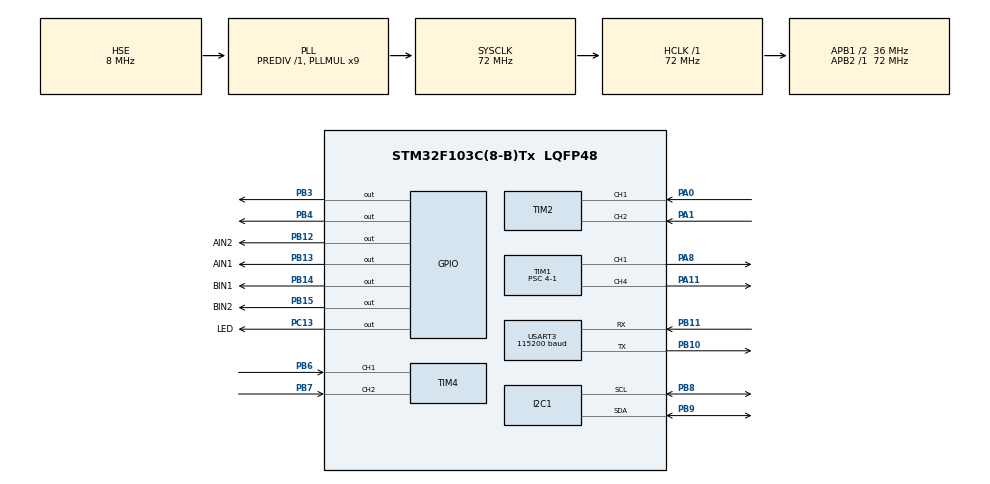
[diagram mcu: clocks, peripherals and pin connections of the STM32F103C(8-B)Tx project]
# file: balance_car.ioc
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Dma.Request0=USART3_RX
Dma.USART3_RX.0.Direction=DMA_PERIPH_TO_MEMORY
Dma.USART3_RX.0.Instance=DMA1_Channel3
Dma.USART3_RX.0.MemDataAlignment=DMA_MDATAALIGN_BYTE
Dma.USART3_RX.0.MemInc=DMA_MINC_ENABLE
Dma.USART3_RX.0.Mode=DMA_NORMAL
Dma.USART3_RX.0.PeriphDataAlignment=DMA_PDATAALIGN_BYTE
Dma.USART3_RX.0.PeriphInc=DMA_PINC_DISABLE
Dma.USART3_RX.0.Priority=DMA_PRIORITY_LOW
FREERTOS.Tasks01=defaultTask,-3,128,StartDefaultTask,Default,NULL,Dynamic,NULL,NULL;sensor,2,128,sensor_task,As external,NULL,Dynamic,NULL,NULL;motor,0,128,motor_task,As external,NULL,Dynamic,NULL,NULL;Bluetooth,0,128,Bluetooth_task,As external,NULL,Dynamic,NULL,NULL
Mcu.Family=STM32F1
Mcu.Name=STM32F103C(8-B)Tx
Mcu.Package=LQFP48
NVIC.DMA1_Channel3_IRQn=true\:5\:0\:false\:false\:true\:true\:false\:true\:true
NVIC.PriorityGroup=NVIC_PRIORITYGROUP_4
NVIC.TIM3_IRQn=true\:15\:0\:false\:false\:true\:false\:false\:true\:true
NVIC.TimeBase=TIM3_IRQn
NVIC.TimeBaseIP=TIM3
NVIC.USART3_IRQn=true\:5\:0\:false\:false\:true\:true\:true\:true\:true
PA0-WKUP.Signal=S_TIM2_CH1_ETR
PA1.Signal=S_TIM2_CH2
PA11.Signal=S_TIM1_CH4
PA13.Mode=Serial_Wire
PA13.Signal=SYS_JTMS-SWDIO
PA14.Mode=Serial_Wire
PA14.Signal=SYS_JTCK-SWCLK
PA8.Signal=S_TIM1_CH1
PB10.Mode=Asynchronous
PB10.Signal=USART3_TX
PB11.Mode=Asynchronous
PB11.Signal=USART3_RX
PB12.GPIO_Label=AIN2
PB12.GPIO_PuPd=GPIO_PULLDOWN
PB12.Signal=GPIO_Output
PB13.GPIO_Label=AIN1
PB13.GPIO_PuPd=GPIO_PULLDOWN
PB13.Signal=GPIO_Output
PB14.GPIO_Label=BIN1
PB14.GPIO_PuPd=GPIO_PULLDOWN
PB14.Signal=GPIO_Output
PB15.GPIO_Label=BIN2
PB15.GPIO_PuPd=GPIO_PULLDOWN
PB15.Signal=GPIO_Output
PB3.GPIO_ModeDefaultOutputPP=GPIO_MODE_OUTPUT_OD
PB3.GPIO_PuPd=GPIO_NOPULL
PB3.GPIO_Speed=GPIO_SPEED_FREQ_HIGH
PB3.PinState=GPIO_PIN_SET
PB3.Signal=GPIO_Output
PB4.GPIO_ModeDefaultOutputPP=GPIO_MODE_OUTPUT_OD
PB4.GPIO_PuPd=GPIO_NOPULL
PB4.GPIO_Speed=GPIO_SPEED_FREQ_HIGH
PB4.PinState=GPIO_PIN_SET
PB4.Signal=GPIO_Output
PB6.Signal=S_TIM4_CH1
PB7.Signal=S_TIM4_CH2
PB8.Mode=I2C
PB8.Signal=I2C1_SCL
PB9.Mode=I2C
PB9.Signal=I2C1_SDA
PC13-TAMPER-RTC.GPIO_Label=LED
PC13-TAMPER-RTC.PinState=GPIO_PIN_SET
PC13-TAMPER-RTC.Signal=GPIO_Output
PD0-OSC_IN.Mode=HSE-External-Oscillator
PD0-OSC_IN.Signal=RCC_OSC_IN
PD1-OSC_OUT.Mode=HSE-External-Oscillator
PD1-OSC_OUT.Signal=RCC_OSC_OUT
ProjectManager.HeapSize=0x200
ProjectManager.StackSize=0x400
ProjectManager.TargetToolchain=MDK-ARM V5
RCC.AHBFreq_Value=72000000
RCC.APB1CLKDivider=RCC_HCLK_DIV2
RCC.APB1Freq_Value=36000000
RCC.APB1TimFreq_Value=72000000
RCC.APB2Freq_Value=72000000
RCC.APB2TimFreq_Value=72000000
RCC.HCLKFreq_Value=72000000
RCC.PLLMUL=RCC_PLL_MUL9
RCC.PLLSourceVirtual=RCC_PLLSOURCE_HSE
RCC.SYSCLKFreq_VALUE=72000000
RCC.SYSCLKSource=RCC_SYSCLKSOURCE_PLLCLK
RCC.USBFreq_Value=72000000
SH.S_TIM1_CH1.0=TIM1_CH1,PWM Generation1 CH1
SH.S_TIM1_CH4.0=TIM1_CH4,PWM Generation4 CH4
SH.S_TIM2_CH1_ETR.0=TIM2_CH1,Encoder_Interface
SH.S_TIM2_CH2.0=TIM2_CH2,Encoder_Interface
SH.S_TIM4_CH1.0=TIM4_CH1,Encoder_Interface
SH.S_TIM4_CH2.0=TIM4_CH2,Encoder_Interface
TIM1.Channel-PWM\ Generation1\ CH1=TIM_CHANNEL_1
TIM1.Channel-PWM\ Generation4\ CH4=TIM_CHANNEL_4
TIM1.Period=900-1
TIM1.Prescaler=4-1
TIM2.EncoderMode=TIM_ENCODERMODE_TI12
TIM2.IC1Filter=8
TIM2.IC2Filter=8
TIM4.EncoderMode=TIM_ENCODERMODE_TI12
TIM4.IC1Filter=8
TIM4.IC2Filter=8
USART3.BaudRate=115200
USART3.VirtualMode=VM_ASYNC
VP_FREERTOS_VS_CMSIS_V1.Mode=CMSIS_V1
VP_SYS_VS_tim3.Mode=TIM3
board=custom

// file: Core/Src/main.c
/* USER CODE BEGIN Header */
/**
  ******************************************************************************
  * @file           : main.c
  * @brief          : Main program body
  ******************************************************************************
  * @attention
  *
  * Copyright (c) 2024 STMicroelectronics.
  * All rights reserved.
  *
  * This software is licensed under terms that can be found in the LICENSE file
  * in the root directory of this software component.
  * If no LICENSE file comes with this software, it is provided AS-IS.
  *
  ******************************************************************************
  */
/* USER CODE END Header */
#include "main.h"
#include "cmsis_os.h"
#include "dma.h"
#include "i2c.h"
#include "tim.h"
#include "usart.h"
#include "gpio.h"

void SystemClock_Config(void);
void MX_FREERTOS_Init(void);

int main(void)
{

  /* MCU Configuration--------------------------------------------------------*/

  /* Reset of all peripherals, Initializes the Flash interface and the Systick. */
  HAL_Init();

  /* Configure the system clock */
  SystemClock_Config();

  /* Initialize all configured peripherals */
  MX_GPIO_Init();
  MX_DMA_Init();
  MX_I2C1_Init();
  MX_TIM1_Init();
  MX_USART3_UART_Init();
  MX_TIM2_Init();
  MX_TIM4_Init();
  /* USER CODE BEGIN 2 */
  OLED_Init();
  OLED_Clear();
  HAL_TIM_PWM_Start(&htim1,TIM_CHANNEL_1);
  HAL_TIM_PWM_Start(&htim1,TIM_CHANNEL_4);
  HAL_TIM_Encoder_Start(&htim2,TIM_CHANNEL_ALL);
  HAL_TIM_Encoder_Start(&htim4,TIM_CHANNEL_ALL);

  while(mpu_init()!=0);
  while(mpu_dmp_init()!=0);
  //OLED_ShowString(0,0,"success",16);
  /* USER CODE END 2 */

  /* Call init function for freertos objects (in cmsis_os2.c) */
  MX_FREERTOS_Init();

  /* Start scheduler */
  osKernelStart();

  /* We should never get here as control is now taken by the scheduler */

  /* Infinite loop */
  while (1)
  {

  }
}

void SystemClock_Config(void)
{
  RCC_OscInitTypeDef RCC_OscInitStruct = {0};
  RCC_ClkInitTypeDef RCC_ClkInitStruct = {0};

  /** Initializes the RCC Oscillators according to the specified parameters
  * in the RCC_OscInitTypeDef structure.
  */
  RCC_OscInitStruct.OscillatorType = RCC_OSCILLATORTYPE_HSE;
  RCC_OscInitStruct.HSEState = RCC_HSE_ON;
  RCC_OscInitStruct.HSEPredivValue = RCC_HSE_PREDIV_DIV1;
  RCC_OscInitStruct.HSIState = RCC_HSI_ON;
  RCC_OscInitStruct.PLL.PLLState = RCC_PLL_ON;
  RCC_OscInitStruct.PLL.PLLSource = RCC_PLLSOURCE_HSE;
  RCC_OscInitStruct.PLL.PLLMUL = RCC_PLL_MUL9;
  if (HAL_RCC_OscConfig(&RCC_OscInitStruct) != HAL_OK)
  {
    Error_Handler();
  }

  /** Initializes the CPU, AHB and APB buses clocks
  */
  RCC_ClkInitStruct.ClockType = RCC_CLOCKTYPE_HCLK|RCC_CLOCKTYPE_SYSCLK
                              |RCC_CLOCKTYPE_PCLK1|RCC_CLOCKTYPE_PCLK2;
  RCC_ClkInitStruct.SYSCLKSource = RCC_SYSCLKSOURCE_PLLCLK;
  RCC_ClkInitStruct.AHBCLKDivider = RCC_SYSCLK_DIV1;
  RCC_ClkInitStruct.APB1CLKDivider = RCC_HCLK_DIV2;
  RCC_ClkInitStruct.APB2CLKDivider = RCC_HCLK_DIV1;

  if (HAL_RCC_ClockConfig(&RCC_ClkInitStruct, FLASH_LATENCY_2) != HAL_OK)
  {
    Error_Handler();
  }
}

void HAL_TIM_PeriodElapsedCallback(TIM_HandleTypeDef *htim)
{
  if (htim->Instance == TIM3) {
    HAL_IncTick();
  }
}

void Error_Handler(void)
{
  __disable_irq();
  while (1)
  {
  }
}

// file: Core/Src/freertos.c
/* USER CODE BEGIN Header */
/**
  ******************************************************************************
  * File Name          : freertos.c
  * Description        : Code for freertos applications
  ******************************************************************************
  * @attention
  *
  * Copyright (c) 2024 STMicroelectronics.
  * All rights reserved.
  *
  * This software is licensed under terms that can be found in the LICENSE file
  * in the root directory of this software component.
  * If no LICENSE file comes with this software, it is provided AS-IS.
  *
  ******************************************************************************
  */
/* USER CODE END Header */

#include "FreeRTOS.h"
#include "task.h"
#include "main.h"
#include "cmsis_os.h"

osThreadId defaultTaskHandle;
osThreadId sensorHandle;
osThreadId motorHandle;
osThreadId BluetoothHandle;

void StartDefaultTask(void const * argument);
extern void sensor_task(void const * argument);
extern void motor_task(void const * argument);
extern void Bluetooth_task(void const * argument);

void MX_FREERTOS_Init(void); /* (MISRA C 2004 rule 8.1) */

/* GetIdleTaskMemory prototype (linked to static allocation support) */
void vApplicationGetIdleTaskMemory( StaticTask_t **ppxIdleTaskTCBBuffer, StackType_t **ppxIdleTaskStackBuffer, uint32_t *pulIdleTaskStackSize );

/* USER CODE BEGIN GET_IDLE_TASK_MEMORY */
static StaticTask_t xIdleTaskTCBBuffer;
static StackType_t xIdleStack[configMINIMAL_STACK_SIZE];

void vApplicationGetIdleTaskMemory( StaticTask_t **ppxIdleTaskTCBBuffer, StackType_t **ppxIdleTaskStackBuffer, uint32_t *pulIdleTaskStackSize )
{
  *ppxIdleTaskTCBBuffer = &xIdleTaskTCBBuffer;
  *ppxIdleTaskStackBuffer = &xIdleStack[0];
  *pulIdleTaskStackSize = configMINIMAL_STACK_SIZE;
  /* place for user code */
}
/* USER CODE END GET_IDLE_TASK_MEMORY */

void MX_FREERTOS_Init(void) {

  /* Create the thread(s) */
  /* definition and creation of defaultTask */
  osThreadDef(defaultTask, StartDefaultTask, osPriorityIdle, 0, 128);
  defaultTaskHandle = osThreadCreate(osThread(defaultTask), NULL);

  /* definition and creation of sensor */
  osThreadDef(sensor, sensor_task, osPriorityHigh, 0, 128);
  sensorHandle = osThreadCreate(osThread(sensor), NULL);

  /* definition and creation of motor */
  osThreadDef(motor, motor_task, osPriorityNormal, 0, 128);
  motorHandle = osThreadCreate(osThread(motor), NULL);

  /* definition and creation of Bluetooth */
  osThreadDef(Bluetooth, Bluetooth_task, osPriorityNormal, 0, 128);
  BluetoothHandle = osThreadCreate(osThread(Bluetooth), NULL);

}

void StartDefaultTask(void const * argument)
{
  for(;;)
  {
    osDelay(1);
  }
}
